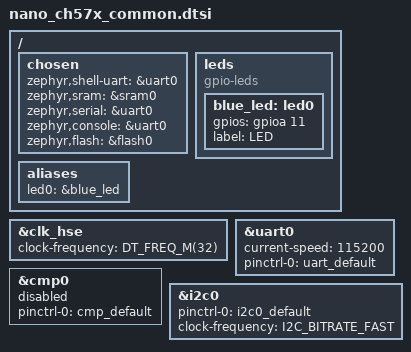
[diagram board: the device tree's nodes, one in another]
/*
 * SPDX-FileCopyrightText: 2026 SMILE (smile.eu)
 *
 * SPDX-License-Identifier: Apache-2.0
 */

#include <zephyr/dt-bindings/gpio/gpio.h>
#include <zephyr/dt-bindings/i2c/i2c.h>
#include "nano_ch57x-pinctrl.dtsi"

/ {
	chosen {
		zephyr,shell-uart = &uart0;
		zephyr,sram = &sram0;
		zephyr,serial = &uart0;
		zephyr,console = &uart0;
		zephyr,flash = &flash0;
	};

	leds {
		compatible = "gpio-leds";

		blue_led: led0 {
			gpios = <&gpioa 11 GPIO_ACTIVE_HIGH>;
			label = "LED";
		};
	};

	aliases {
		led0 = &blue_led;
	};
};

&clk_hse {
	clock-frequency = <DT_FREQ_M(32)>;
};

&uart0 {
	status = "okay";
	current-speed = <115200>;
	pinctrl-0 = <&uart_default>;
	pinctrl-names = "default";
};

&cmp0 {
	status = "disabled";
	pinctrl-0 = <&cmp_default>;
	pinctrl-names = "default";
};

&i2c0 {
	pinctrl-0 = <&i2c0_default>;
	pinctrl-names = "default";
	clock-frequency = <I2C_BITRATE_FAST>;
};
